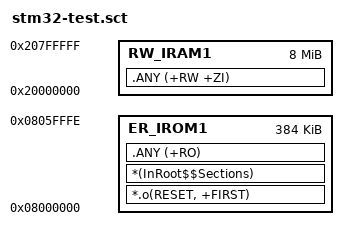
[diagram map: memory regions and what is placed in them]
LR_IROM1 0x08000000 0x0005FFFF  {    ; load region size_region
  ER_IROM1 0x08000000 0x0005FFFF  {  ; load address = execution address
   *.o(RESET, +FIRST)
   *(InRoot$$Sections)
   .ANY (+RO)
  }
  RW_IRAM1 0x20000000 0x00800000  {  ; RW data
   .ANY (+RW +ZI)
  } 
}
